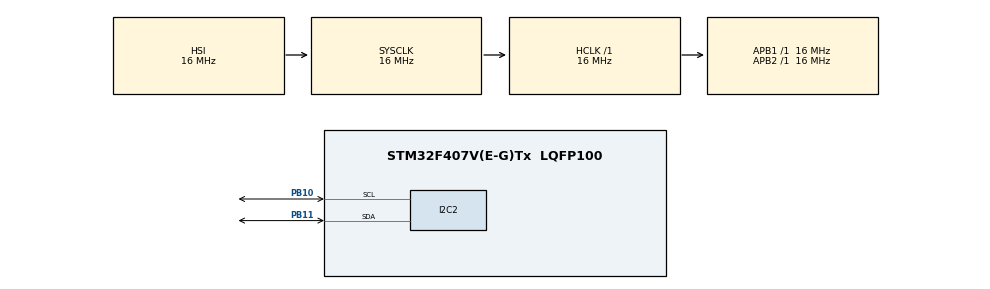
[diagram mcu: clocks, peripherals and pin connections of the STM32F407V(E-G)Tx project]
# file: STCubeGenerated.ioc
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Mcu.Family=STM32F4
Mcu.Name=STM32F407V(E-G)Tx
Mcu.Package=LQFP100
NVIC.PriorityGroup=NVIC_PRIORITYGROUP_4
PB10.Mode=I2C
PB10.Signal=I2C2_SCL
PB11.Mode=I2C
PB11.Signal=I2C2_SDA
PH0-OSC_IN.Mode=HSE-External-Oscillator
PH0-OSC_IN.Signal=RCC_OSC_IN
PH1-OSC_OUT.Mode=HSE-External-Oscillator
PH1-OSC_OUT.Signal=RCC_OSC_OUT
ProjectManager.HeapSize=0x200
ProjectManager.StackSize=0x400
ProjectManager.TargetToolchain=MDK-ARM V5
RCC.AHBFreq_Value=16000000
RCC.APB1Freq_Value=16000000
RCC.APB2Freq_Value=16000000
RCC.CortexFreq_Value=16000000
RCC.HSE_VALUE=25000000
RCC.HSI_VALUE=16000000
RCC.LSE_VALUE=32768
RCC.SYSCLKFreq_VALUE=16000000
RCC.VCOOutputFreq_Value=192000000
board=custom

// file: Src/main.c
/* USER CODE BEGIN Header */
/**
  ******************************************************************************
  * @file           : main.c
  * @brief          : Main program body
  ******************************************************************************
  * @attention
  *
  * Copyright (c) 2023 STMicroelectronics.
  * All rights reserved.
  *
  * This software is licensed under terms that can be found in the LICENSE file
  * in the root directory of this software component.
  * If no LICENSE file comes with this software, it is provided AS-IS.
  *
  ******************************************************************************
  */
/* USER CODE END Header */
#include "main.h"

I2C_HandleTypeDef hi2c2;

void SystemClock_Config(void);
static void MX_GPIO_Init(void);
static void MX_I2C2_Init(void);

int main(void)
{

  /* MCU Configuration--------------------------------------------------------*/

  /* Reset of all peripherals, Initializes the Flash interface and the Systick. */
  HAL_Init();

  /* Configure the system clock */
  SystemClock_Config();

  /* Initialize all configured peripherals */
  MX_GPIO_Init();
  MX_I2C2_Init();

  /* Infinite loop */
  /* USER CODE BEGIN WHILE */
	uint8_t buffer[5];
	buffer[0]=0x20>>1;
	buffer[1]=0xFF;

	uint16_t address=0x40;
	uint8_t data= 0x00;
	HAL_I2C_MODULE_ENABLED(&hi2c2);

	//__HAL_I2C_ENABLE(&hi2c2);
HAL_I2C_Master_Transmit (&hi2c2, 0x20, &data, 1, 50);
  while (1)
  {

		//HAL_I2C_Master_Transmit(&hi2c2, address[0], data, 1, 100);
		//HAL_I2C_Master_Transmit(&hi2c2, 0x40&1, &a2, 1, 100);

		HAL_I2C_Master_Transmit (&hi2c2, 0x20, &data, 1, 50);
		//HAL_Delay(10);
    /* USER CODE END WHILE */

  }
}

void SystemClock_Config(void)
{
  RCC_OscInitTypeDef RCC_OscInitStruct = {0};
  RCC_ClkInitTypeDef RCC_ClkInitStruct = {0};

  /** Configure the main internal regulator output voltage
  */
  __HAL_RCC_PWR_CLK_ENABLE();
  __HAL_PWR_VOLTAGESCALING_CONFIG(PWR_REGULATOR_VOLTAGE_SCALE1);

  /** Initializes the RCC Oscillators according to the specified parameters
  * in the RCC_OscInitTypeDef structure.
  */
  RCC_OscInitStruct.OscillatorType = RCC_OSCILLATORTYPE_HSI;
  RCC_OscInitStruct.HSIState = RCC_HSI_ON;
  RCC_OscInitStruct.HSICalibrationValue = RCC_HSICALIBRATION_DEFAULT;
  RCC_OscInitStruct.PLL.PLLState = RCC_PLL_NONE;
  if (HAL_RCC_OscConfig(&RCC_OscInitStruct) != HAL_OK)
  {
    Error_Handler();
  }

  /** Initializes the CPU, AHB and APB buses clocks
  */
  RCC_ClkInitStruct.ClockType = RCC_CLOCKTYPE_HCLK|RCC_CLOCKTYPE_SYSCLK
                              |RCC_CLOCKTYPE_PCLK1|RCC_CLOCKTYPE_PCLK2;
  RCC_ClkInitStruct.SYSCLKSource = RCC_SYSCLKSOURCE_HSI;
  RCC_ClkInitStruct.AHBCLKDivider = RCC_SYSCLK_DIV1;
  RCC_ClkInitStruct.APB1CLKDivider = RCC_HCLK_DIV1;
  RCC_ClkInitStruct.APB2CLKDivider = RCC_HCLK_DIV1;

  if (HAL_RCC_ClockConfig(&RCC_ClkInitStruct, FLASH_LATENCY_0) != HAL_OK)
  {
    Error_Handler();
  }
}

static void MX_I2C2_Init(void)
{

  hi2c2.Instance = I2C2;
  hi2c2.Init.ClockSpeed = 100000;
  hi2c2.Init.DutyCycle = I2C_DUTYCYCLE_2;
  hi2c2.Init.OwnAddress1 = 0;
  hi2c2.Init.AddressingMode = I2C_ADDRESSINGMODE_7BIT;
  hi2c2.Init.DualAddressMode = I2C_DUALADDRESS_DISABLE;
  hi2c2.Init.OwnAddress2 = 0;
  hi2c2.Init.GeneralCallMode = I2C_GENERALCALL_DISABLE;
  hi2c2.Init.NoStretchMode = I2C_NOSTRETCH_DISABLE;
  if (HAL_I2C_Init(&hi2c2) != HAL_OK)
  {
    Error_Handler();
  }

}

static void MX_GPIO_Init(void)
{

  /* GPIO Ports Clock Enable */
  __HAL_RCC_GPIOH_CLK_ENABLE();
  __HAL_RCC_GPIOB_CLK_ENABLE();

}

void Error_Handler(void)
{
  __disable_irq();
  while (1)
  {
  }
}
